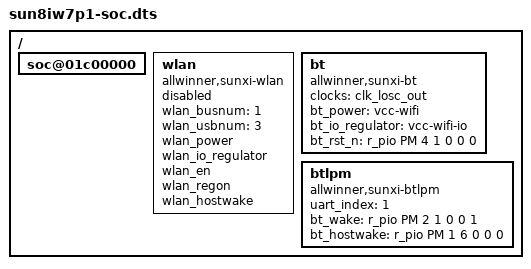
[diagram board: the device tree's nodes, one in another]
/*
 * Allwinner Technology CO., Ltd. sun8iw7p1 soc board.
 *
 */

/dts-v1/;

#include "sun8iw7p1.dtsi"

/{

	soc@01c00000 {
	};
	wlan:wlan {
		compatible = "allwinner,sunxi-wlan";
		wlan_busnum = <1>;
		wlan_usbnum = <3>;
		wlan_power;
		wlan_io_regulator;
		wlan_en;
		wlan_regon;
		wlan_hostwake;
		status = "disabled";
	};

	bt:bt {
	        compatible = "allwinner,sunxi-bt";
		clocks = <&clk_losc_out>;
		bt_power = "vcc-wifi";
		bt_io_regulator = "vcc-wifi-io";
		bt_rst_n = <&r_pio PM 4 1 0 0 0>;
		status = "okay";
	};

	btlpm:btlpm {
	        compatible = "allwinner,sunxi-btlpm";
		uart_index = <1>;
		bt_wake = <&r_pio PM 2 1 0 0 1>;
		bt_hostwake = <&r_pio PM 1 6 0 0 0>;
		status = "okay";
	};

};
